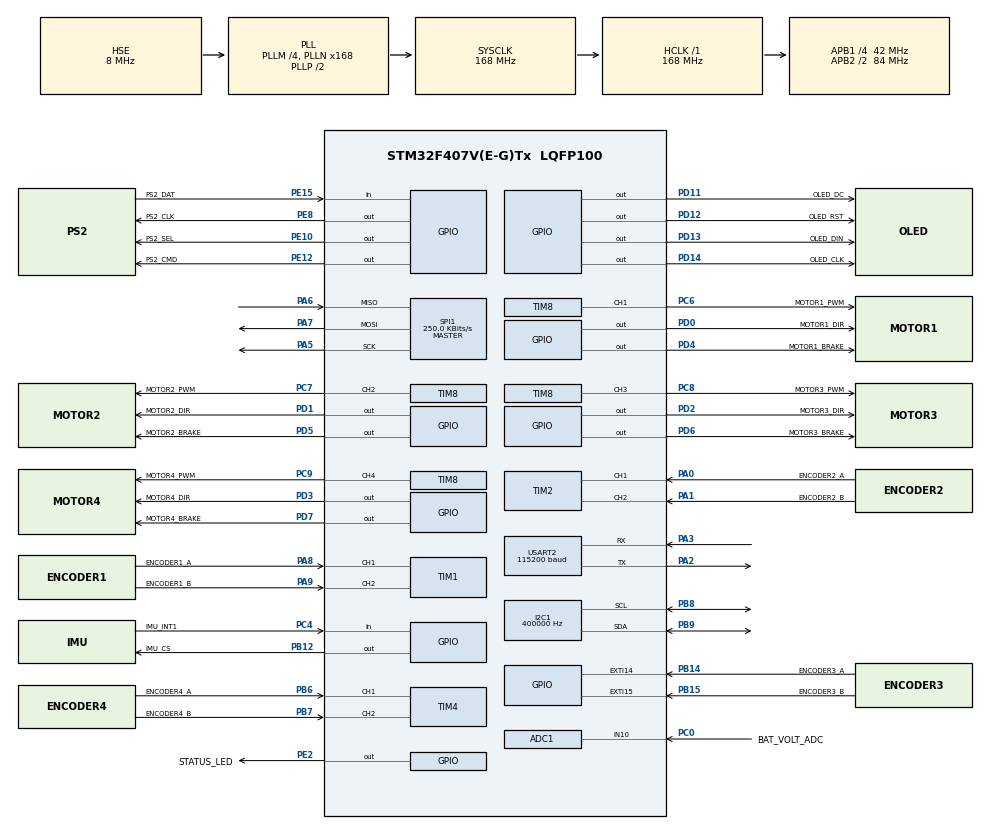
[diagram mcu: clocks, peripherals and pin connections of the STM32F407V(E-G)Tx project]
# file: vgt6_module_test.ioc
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ADC1.Channel-10\#ChannelRegularConversion=ADC_CHANNEL_10
ADC1.NbrOfConversionFlag=1
ADC1.Rank-10\#ChannelRegularConversion=1
ADC1.SamplingTime-10\#ChannelRegularConversion=ADC_SAMPLETIME_144CYCLES
ADC1.master=1
Dma.Request0=USART2_RX
Dma.Request1=USART2_TX
Dma.USART2_RX.0.Direction=DMA_PERIPH_TO_MEMORY
Dma.USART2_RX.0.FIFOMode=DMA_FIFOMODE_DISABLE
Dma.USART2_RX.0.Instance=DMA1_Stream5
Dma.USART2_RX.0.MemDataAlignment=DMA_MDATAALIGN_BYTE
Dma.USART2_RX.0.MemInc=DMA_MINC_ENABLE
Dma.USART2_RX.0.Mode=DMA_NORMAL
Dma.USART2_RX.0.PeriphDataAlignment=DMA_PDATAALIGN_BYTE
Dma.USART2_RX.0.PeriphInc=DMA_PINC_DISABLE
Dma.USART2_RX.0.Priority=DMA_PRIORITY_LOW
Dma.USART2_TX.1.Direction=DMA_MEMORY_TO_PERIPH
Dma.USART2_TX.1.FIFOMode=DMA_FIFOMODE_DISABLE
Dma.USART2_TX.1.Instance=DMA1_Stream6
Dma.USART2_TX.1.MemDataAlignment=DMA_MDATAALIGN_BYTE
Dma.USART2_TX.1.MemInc=DMA_MINC_ENABLE
Dma.USART2_TX.1.Mode=DMA_NORMAL
Dma.USART2_TX.1.PeriphDataAlignment=DMA_PDATAALIGN_BYTE
Dma.USART2_TX.1.PeriphInc=DMA_PINC_DISABLE
Dma.USART2_TX.1.Priority=DMA_PRIORITY_LOW
I2C1.ClockSpeed=400000
I2C1.I2C_Mode=I2C_Fast
Mcu.Family=STM32F4
Mcu.Name=STM32F407V(E-G)Tx
Mcu.Package=LQFP100
NVIC.DMA1_Stream5_IRQn=true\:5\:0\:false\:false\:true\:true\:true\:true
NVIC.DMA1_Stream6_IRQn=true\:5\:0\:false\:false\:true\:true\:true\:true
NVIC.EXTI15_10_IRQn=true\:5\:0\:false\:false\:true\:true\:true\:true
NVIC.I2C1_EV_IRQn=true\:5\:0\:false\:false\:true\:true\:true\:true
NVIC.I2C1_ER_IRQn=true\:5\:0\:false\:false\:true\:true\:true\:true
NVIC.PriorityGroup=NVIC_PRIORITYGROUP_4
NVIC.USART2_IRQn=true\:5\:0\:false\:false\:true\:true\:true\:true
PA0-WKUP.GPIO_Label=ENCODER2_A
PA0-WKUP.Signal=S_TIM2_CH1_ETR
PA1.GPIO_Label=ENCODER2_B
PA1.Signal=S_TIM2_CH2
PA13.Mode=Serial_Wire
PA13.Signal=SYS_JTMS-SWDIO
PA14.Mode=Serial_Wire
PA14.Signal=SYS_JTCK-SWCLK
PA2.Mode=Asynchronous
PA2.Signal=USART2_TX
PA3.Mode=Asynchronous
PA3.Signal=USART2_RX
PA5.Mode=Full_Duplex_Master
PA5.Signal=SPI1_SCK
PA6.Mode=Full_Duplex_Master
PA6.Signal=SPI1_MISO
PA7.Mode=Full_Duplex_Master
PA7.Signal=SPI1_MOSI
PA8.GPIO_Label=ENCODER1_A
PA8.Signal=S_TIM1_CH1
PA9.GPIO_Label=ENCODER1_B
PA9.Signal=S_TIM1_CH2
PB8.Mode=I2C
PB8.Signal=I2C1_SCL
PB9.Mode=I2C
PB9.Signal=I2C1_SDA
PB12.GPIO_Label=IMU_CS
PB12.GPIO_PuPd=GPIO_PULLUP
PB12.PinState=GPIO_PIN_SET
PB12.Signal=GPIO_Output
PB14.GPIO_Label=ENCODER3_A
PB14.GPIO_ModeDefaultEXTI=GPIO_MODE_IT_RISING_FALLING
PB14.Signal=GPXTI14
PB15.GPIO_Label=ENCODER3_B
PB15.GPIO_ModeDefaultEXTI=GPIO_MODE_IT_RISING_FALLING
PB15.Signal=GPXTI15
PB6.GPIO_Label=ENCODER4_A
PB6.Signal=S_TIM4_CH1
PB7.GPIO_Label=ENCODER4_B
PB7.Signal=S_TIM4_CH2
PE8.GPIO_Label=PS2_CLK
PE8.GPIO_PuPd=GPIO_PULLUP
PE8.PinState=GPIO_PIN_SET
PE8.Signal=GPIO_Output
PE10.GPIO_Label=PS2_SEL
PE10.GPIO_PuPd=GPIO_PULLUP
PE10.PinState=GPIO_PIN_SET
PE10.Signal=GPIO_Output
PE12.GPIO_Label=PS2_CMD
PE12.GPIO_PuPd=GPIO_PULLUP
PE12.PinState=GPIO_PIN_SET
PE12.Signal=GPIO_Output
PE15.GPIO_Label=PS2_DAT
PE15.GPIO_PuPd=GPIO_PULLUP
PE15.Signal=GPIO_Input
PC0.GPIO_Label=BAT_VOLT_ADC
PC0.Signal=ADCx_IN10
PC4.GPIO_Label=IMU_INT1
PC4.GPIO_PuPd=GPIO_PULLDOWN
PC4.Signal=GPIO_Input
PC6.GPIO_Label=MOTOR1_PWM
PC6.Signal=S_TIM8_CH1
PC7.GPIO_Label=MOTOR2_PWM
PC7.Signal=S_TIM8_CH2
PC8.GPIO_Label=MOTOR3_PWM
PC8.Signal=S_TIM8_CH3
PC9.GPIO_Label=MOTOR4_PWM
PC9.Signal=S_TIM8_CH4
PD0.GPIO_Label=MOTOR1_DIR
PD0.PinState=GPIO_PIN_RESET
PD0.Signal=GPIO_Output
PD1.GPIO_Label=MOTOR2_DIR
PD1.PinState=GPIO_PIN_RESET
PD1.Signal=GPIO_Output
PD11.GPIO_Label=OLED_DC
PD11.PinState=GPIO_PIN_RESET
PD11.Signal=GPIO_Output
PD12.GPIO_Label=OLED_RST
PD12.PinState=GPIO_PIN_SET
PD12.Signal=GPIO_Output
PD13.GPIO_Label=OLED_DIN
PD13.PinState=GPIO_PIN_SET
PD13.Signal=GPIO_Output
PD14.GPIO_Label=OLED_CLK
PD14.PinState=GPIO_PIN_SET
PD14.Signal=GPIO_Output
PD2.GPIO_Label=MOTOR3_DIR
PD2.PinState=GPIO_PIN_RESET
PD2.Signal=GPIO_Output
PD3.GPIO_Label=MOTOR4_DIR
PD3.PinState=GPIO_PIN_RESET
PD3.Signal=GPIO_Output
PD4.GPIO_Label=MOTOR1_BRAKE
PD4.PinState=GPIO_PIN_RESET
PD4.Signal=GPIO_Output
PD5.GPIO_Label=MOTOR2_BRAKE
PD5.PinState=GPIO_PIN_RESET
PD5.Signal=GPIO_Output
PD6.GPIO_Label=MOTOR3_BRAKE
PD6.PinState=GPIO_PIN_RESET
PD6.Signal=GPIO_Output
PD7.GPIO_Label=MOTOR4_BRAKE
PD7.PinState=GPIO_PIN_RESET
PD7.Signal=GPIO_Output
PE2.GPIO_Label=STATUS_LED
PE2.PinState=GPIO_PIN_RESET
PE2.Signal=GPIO_Output
PH0-OSC_IN.Mode=HSE-External-Oscillator
PH0-OSC_IN.Signal=RCC_OSC_IN
PH1-OSC_OUT.Mode=HSE-External-Oscillator
PH1-OSC_OUT.Signal=RCC_OSC_OUT
ProjectManager.HeapSize=0x200
ProjectManager.StackSize=0x1000
ProjectManager.TargetToolchain=MDK-ARM V5
RCC.48MHZClocksFreq_Value=84000000
RCC.AHBFreq_Value=168000000
RCC.APB1CLKDivider=RCC_HCLK_DIV4
RCC.APB1Freq_Value=42000000
RCC.APB1TimFreq_Value=84000000
RCC.APB2CLKDivider=RCC_HCLK_DIV2
RCC.APB2Freq_Value=84000000
RCC.APB2TimFreq_Value=168000000
RCC.CortexFreq_Value=168000000
RCC.HCLKFreq_Value=168000000
RCC.HSE_VALUE=8000000
RCC.HSI_VALUE=16000000
RCC.LSE_VALUE=32768
RCC.PLLM=4
RCC.PLLN=168
RCC.PLLSourceVirtual=RCC_PLLSOURCE_HSE
RCC.SYSCLKFreq_VALUE=168000000
RCC.SYSCLKSource=RCC_SYSCLKSOURCE_PLLCLK
RCC.VCOOutputFreq_Value=336000000
SH.ADCx_IN10.0=ADC1_IN10,IN10
SH.S_TIM1_CH1.0=TIM1_CH1,Encoder_Interface
SH.S_TIM1_CH2.0=TIM1_CH2,Encoder_Interface
SH.S_TIM2_CH1_ETR.0=TIM2_CH1,Encoder_Interface
SH.S_TIM2_CH2.0=TIM2_CH2,Encoder_Interface
SH.S_TIM4_CH1.0=TIM4_CH1,Encoder_Interface
SH.S_TIM4_CH2.0=TIM4_CH2,Encoder_Interface
SH.S_TIM8_CH1.0=TIM8_CH1,PWM Generation1 CH1
SH.S_TIM8_CH2.0=TIM8_CH2,PWM Generation2 CH2
SH.S_TIM8_CH3.0=TIM8_CH3,PWM Generation3 CH3
SH.S_TIM8_CH4.0=TIM8_CH4,PWM Generation4 CH4
SPI1.BaudRatePrescaler=SPI_BAUDRATEPRESCALER_64
SPI1.CLKPhase=SPI_PHASE_2EDGE
SPI1.CLKPolarity=SPI_POLARITY_HIGH
SPI1.CRCCalculation=SPI_CRCCALCULATION_DISABLE
SPI1.CalculateBaudRate=250.0 KBits/s
SPI1.DataSize=SPI_DATASIZE_8BIT
SPI1.Direction=SPI_DIRECTION_2LINES
SPI1.FirstBit=SPI_FIRSTBIT_MSB
SPI1.Mode=SPI_MODE_MASTER
SPI1.NSS=SPI_NSS_SOFT
SPI1.VirtualType=VM_MASTER
TIM1.EncoderMode=TIM_ENCODERMODE_TI12
TIM1.IC1Filter=10
TIM1.IC2Filter=10
TIM2.EncoderMode=TIM_ENCODERMODE_TI12
TIM2.IC1Filter=10
TIM2.IC2Filter=10
TIM4.EncoderMode=TIM_ENCODERMODE_TI12
TIM4.IC1Filter=10
TIM4.IC2Filter=10
TIM8.Channel-PWM\ Generation1\ CH1=TIM_CHANNEL_1
TIM8.Channel-PWM\ Generation2\ CH2=TIM_CHANNEL_2
TIM8.Channel-PWM\ Generation3\ CH3=TIM_CHANNEL_3
TIM8.Channel-PWM\ Generation4\ CH4=TIM_CHANNEL_4
TIM8.OCMode_PWM=TIM_OCMODE_PWM2
TIM8.Period=16799
TIM8.Prescaler=0
USART2.BaudRate=115200
USART2.VirtualMode=VM_ASYNC
board=custom

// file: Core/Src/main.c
/* USER CODE BEGIN Header */
/**
  ******************************************************************************
  * @file           : main.c
  * @brief          : Main program body
  ******************************************************************************
  * @attention
  *
  * Copyright (c) 2026 STMicroelectronics.
  * All rights reserved.
  *
  * This software is licensed under terms that can be found in the LICENSE file
  * in the root directory of this software component.
  * If no LICENSE file comes with this software, it is provided AS-IS.
  *
  ******************************************************************************
  */
/* USER CODE END Header */
#include "main.h"

/* USER CODE BEGIN Includes */
#include "app.h"
/* USER CODE END Includes */

ADC_HandleTypeDef hadc1;

I2C_HandleTypeDef hi2c1;

SPI_HandleTypeDef hspi1;

TIM_HandleTypeDef htim1;
TIM_HandleTypeDef htim2;
TIM_HandleTypeDef htim4;
TIM_HandleTypeDef htim8;

UART_HandleTypeDef huart2;
DMA_HandleTypeDef hdma_usart2_rx;
DMA_HandleTypeDef hdma_usart2_tx;

void SystemClock_Config(void);
static void MX_GPIO_Init(void);
static void MX_DMA_Init(void);
static void MX_ADC1_Init(void);
static void MX_I2C1_Init(void);
static void MX_SPI1_Init(void);
static void MX_TIM1_Init(void);
static void MX_TIM2_Init(void);
static void MX_TIM4_Init(void);
static void MX_TIM8_Init(void);
static void MX_USART2_UART_Init(void);

int main(void)
{

  /* MCU Configuration--------------------------------------------------------*/

  /* Reset of all peripherals, Initializes the Flash interface and the Systick. */
  HAL_Init();

  /* Configure the system clock */
  SystemClock_Config();

  /* Initialize all configured peripherals */
  MX_GPIO_Init();
  MX_DMA_Init();
  MX_ADC1_Init();
  MX_SPI1_Init();
  MX_TIM1_Init();
  MX_TIM2_Init();
  MX_TIM4_Init();
  MX_TIM8_Init();
  MX_USART2_UART_Init();
  MX_I2C1_Init();
  /* USER CODE BEGIN 2 */
  App_Init();
  /* USER CODE END 2 */

  /* Infinite loop */
  while (1)
  {

    /* USER CODE BEGIN 3 */
    App_Process();
  }
  /* USER CODE END 3 */
}

void SystemClock_Config(void)
{
  RCC_OscInitTypeDef RCC_OscInitStruct = {0};
  RCC_ClkInitTypeDef RCC_ClkInitStruct = {0};

  /** Configure the main internal regulator output voltage
  */
  __HAL_RCC_PWR_CLK_ENABLE();
  __HAL_PWR_VOLTAGESCALING_CONFIG(PWR_REGULATOR_VOLTAGE_SCALE1);

  /** Initializes the RCC Oscillators according to the specified parameters
  * in the RCC_OscInitTypeDef structure.
  */
  RCC_OscInitStruct.OscillatorType = RCC_OSCILLATORTYPE_HSE;
  RCC_OscInitStruct.HSEState = RCC_HSE_ON;
  RCC_OscInitStruct.PLL.PLLState = RCC_PLL_ON;
  RCC_OscInitStruct.PLL.PLLSource = RCC_PLLSOURCE_HSE;
  RCC_OscInitStruct.PLL.PLLM = 4;
  RCC_OscInitStruct.PLL.PLLN = 168;
  RCC_OscInitStruct.PLL.PLLP = RCC_PLLP_DIV2;
  RCC_OscInitStruct.PLL.PLLQ = 4;
  if (HAL_RCC_OscConfig(&RCC_OscInitStruct) != HAL_OK)
  {
    Error_Handler();
  }

  /** Initializes the CPU, AHB and APB buses clocks
  */
  RCC_ClkInitStruct.ClockType = RCC_CLOCKTYPE_HCLK|RCC_CLOCKTYPE_SYSCLK
                              |RCC_CLOCKTYPE_PCLK1|RCC_CLOCKTYPE_PCLK2;
  RCC_ClkInitStruct.SYSCLKSource = RCC_SYSCLKSOURCE_PLLCLK;
  RCC_ClkInitStruct.AHBCLKDivider = RCC_SYSCLK_DIV1;
  RCC_ClkInitStruct.APB1CLKDivider = RCC_HCLK_DIV4;
  RCC_ClkInitStruct.APB2CLKDivider = RCC_HCLK_DIV2;

  if (HAL_RCC_ClockConfig(&RCC_ClkInitStruct, FLASH_LATENCY_5) != HAL_OK)
  {
    Error_Handler();
  }
}

static void MX_ADC1_Init(void)
{

  ADC_ChannelConfTypeDef sConfig = {0};

  /** Configure the global features of the ADC (Clock, Resolution, Data Alignment and number of conversion)
  */
  hadc1.Instance = ADC1;
  hadc1.Init.ClockPrescaler = ADC_CLOCK_SYNC_PCLK_DIV4;
  hadc1.Init.Resolution = ADC_RESOLUTION_12B;
  hadc1.Init.ScanConvMode = DISABLE;
  hadc1.Init.ContinuousConvMode = DISABLE;
  hadc1.Init.DiscontinuousConvMode = DISABLE;
  hadc1.Init.ExternalTrigConvEdge = ADC_EXTERNALTRIGCONVEDGE_NONE;
  hadc1.Init.ExternalTrigConv = ADC_SOFTWARE_START;
  hadc1.Init.DataAlign = ADC_DATAALIGN_RIGHT;
  hadc1.Init.NbrOfConversion = 1;
  hadc1.Init.DMAContinuousRequests = DISABLE;
  hadc1.Init.EOCSelection = ADC_EOC_SINGLE_CONV;
  if (HAL_ADC_Init(&hadc1) != HAL_OK)
  {
    Error_Handler();
  }

  /** Configure for the selected ADC regular channel its corresponding rank in the sequencer and its sample time.
  */
  sConfig.Channel = ADC_CHANNEL_10;
  sConfig.Rank = 1;
  sConfig.SamplingTime = ADC_SAMPLETIME_144CYCLES;
  if (HAL_ADC_ConfigChannel(&hadc1, &sConfig) != HAL_OK)
  {
    Error_Handler();
  }

}

static void MX_SPI1_Init(void)
{

  /* SPI1 parameter configuration*/
  hspi1.Instance = SPI1;
  hspi1.Init.Mode = SPI_MODE_MASTER;
  hspi1.Init.Direction = SPI_DIRECTION_2LINES;
  hspi1.Init.DataSize = SPI_DATASIZE_8BIT;
  hspi1.Init.CLKPolarity = SPI_POLARITY_HIGH;
  hspi1.Init.CLKPhase = SPI_PHASE_2EDGE;
  hspi1.Init.NSS = SPI_NSS_SOFT;
  hspi1.Init.BaudRatePrescaler = SPI_BAUDRATEPRESCALER_64;
  hspi1.Init.FirstBit = SPI_FIRSTBIT_MSB;
  hspi1.Init.TIMode = SPI_TIMODE_DISABLE;
  hspi1.Init.CRCCalculation = SPI_CRCCALCULATION_DISABLE;
  hspi1.Init.CRCPolynomial = 10;
  if (HAL_SPI_Init(&hspi1) != HAL_OK)
  {
    Error_Handler();
  }

}

static void MX_TIM1_Init(void)
{

  TIM_Encoder_InitTypeDef sConfig = {0};
  TIM_MasterConfigTypeDef sMasterConfig = {0};

  htim1.Instance = TIM1;
  htim1.Init.Prescaler = 0;
  htim1.Init.CounterMode = TIM_COUNTERMODE_UP;
  htim1.Init.Period = 65535;
  htim1.Init.ClockDivision = TIM_CLOCKDIVISION_DIV1;
  htim1.Init.RepetitionCounter = 0;
  htim1.Init.AutoReloadPreload = TIM_AUTORELOAD_PRELOAD_DISABLE;
  sConfig.EncoderMode = TIM_ENCODERMODE_TI12;
  sConfig.IC1Polarity = TIM_ICPOLARITY_RISING;
  sConfig.IC1Selection = TIM_ICSELECTION_DIRECTTI;
  sConfig.IC1Prescaler = TIM_ICPSC_DIV1;
  sConfig.IC1Filter = 10;
  sConfig.IC2Polarity = TIM_ICPOLARITY_RISING;
  sConfig.IC2Selection = TIM_ICSELECTION_DIRECTTI;
  sConfig.IC2Prescaler = TIM_ICPSC_DIV1;
  sConfig.IC2Filter = 10;
  if (HAL_TIM_Encoder_Init(&htim1, &sConfig) != HAL_OK)
  {
    Error_Handler();
  }
  sMasterConfig.MasterOutputTrigger = TIM_TRGO_RESET;
  sMasterConfig.MasterSlaveMode = TIM_MASTERSLAVEMODE_DISABLE;
  if (HAL_TIMEx_MasterConfigSynchronization(&htim1, &sMasterConfig) != HAL_OK)
  {
    Error_Handler();
  }

}

static void MX_TIM2_Init(void)
{

  TIM_Encoder_InitTypeDef sConfig = {0};
  TIM_MasterConfigTypeDef sMasterConfig = {0};

  htim2.Instance = TIM2;
  htim2.Init.Prescaler = 0;
  htim2.Init.CounterMode = TIM_COUNTERMODE_UP;
  htim2.Init.Period = 4294967295;
  htim2.Init.ClockDivision = TIM_CLOCKDIVISION_DIV1;
  htim2.Init.AutoReloadPreload = TIM_AUTORELOAD_PRELOAD_DISABLE;
  sConfig.EncoderMode = TIM_ENCODERMODE_TI12;
  sConfig.IC1Polarity = TIM_ICPOLARITY_RISING;
  sConfig.IC1Selection = TIM_ICSELECTION_DIRECTTI;
  sConfig.IC1Prescaler = TIM_ICPSC_DIV1;
  sConfig.IC1Filter = 10;
  sConfig.IC2Polarity = TIM_ICPOLARITY_RISING;
  sConfig.IC2Selection = TIM_ICSELECTION_DIRECTTI;
  sConfig.IC2Prescaler = TIM_ICPSC_DIV1;
  sConfig.IC2Filter = 10;
  if (HAL_TIM_Encoder_Init(&htim2, &sConfig) != HAL_OK)
  {
    Error_Handler();
  }
  sMasterConfig.MasterOutputTrigger = TIM_TRGO_RESET;
  sMasterConfig.MasterSlaveMode = TIM_MASTERSLAVEMODE_DISABLE;
  if (HAL_TIMEx_MasterConfigSynchronization(&htim2, &sMasterConfig) != HAL_OK)
  {
    Error_Handler();
  }

}

static void MX_TIM4_Init(void)
{

  TIM_Encoder_InitTypeDef sConfig = {0};
  TIM_MasterConfigTypeDef sMasterConfig = {0};

  htim4.Instance = TIM4;
  htim4.Init.Prescaler = 0;
  htim4.Init.CounterMode = TIM_COUNTERMODE_UP;
  htim4.Init.Period = 65535;
  htim4.Init.ClockDivision = TIM_CLOCKDIVISION_DIV1;
  htim4.Init.AutoReloadPreload = TIM_AUTORELOAD_PRELOAD_DISABLE;
  sConfig.EncoderMode = TIM_ENCODERMODE_TI12;
  sConfig.IC1Polarity = TIM_ICPOLARITY_RISING;
  sConfig.IC1Selection = TIM_ICSELECTION_DIRECTTI;
  sConfig.IC1Prescaler = TIM_ICPSC_DIV1;
  sConfig.IC1Filter = 10;
  sConfig.IC2Polarity = TIM_ICPOLARITY_RISING;
  sConfig.IC2Selection = TIM_ICSELECTION_DIRECTTI;
  sConfig.IC2Prescaler = TIM_ICPSC_DIV1;
  sConfig.IC2Filter = 10;
  if (HAL_TIM_Encoder_Init(&htim4, &sConfig) != HAL_OK)
  {
    Error_Handler();
  }
  sMasterConfig.MasterOutputTrigger = TIM_TRGO_RESET;
  sMasterConfig.MasterSlaveMode = TIM_MASTERSLAVEMODE_DISABLE;
  if (HAL_TIMEx_MasterConfigSynchronization(&htim4, &sMasterConfig) != HAL_OK)
  {
    Error_Handler();
  }

}

static void MX_TIM8_Init(void)
{

  TIM_MasterConfigTypeDef sMasterConfig = {0};
  TIM_OC_InitTypeDef sConfigOC = {0};
  TIM_BreakDeadTimeConfigTypeDef sBreakDeadTimeConfig = {0};

  htim8.Instance = TIM8;
  htim8.Init.Prescaler = 0;
  htim8.Init.CounterMode = TIM_COUNTERMODE_UP;
  htim8.Init.Period = 16799;
  htim8.Init.ClockDivision = TIM_CLOCKDIVISION_DIV1;
  htim8.Init.RepetitionCounter = 0;
  htim8.Init.AutoReloadPreload = TIM_AUTORELOAD_PRELOAD_DISABLE;
  if (HAL_TIM_PWM_Init(&htim8) != HAL_OK)
  {
    Error_Handler();
  }
  sMasterConfig.MasterOutputTrigger = TIM_TRGO_RESET;
  sMasterConfig.MasterSlaveMode = TIM_MASTERSLAVEMODE_DISABLE;
  if (HAL_TIMEx_MasterConfigSynchronization(&htim8, &sMasterConfig) != HAL_OK)
  {
    Error_Handler();
  }
  sConfigOC.OCMode = TIM_OCMODE_PWM2;
  sConfigOC.Pulse = 0;
  sConfigOC.OCPolarity = TIM_OCPOLARITY_HIGH;
  sConfigOC.OCNPolarity = TIM_OCNPOLARITY_HIGH;
  sConfigOC.OCFastMode = TIM_OCFAST_DISABLE;
  sConfigOC.OCIdleState = TIM_OCIDLESTATE_RESET;
  sConfigOC.OCNIdleState = TIM_OCNIDLESTATE_RESET;
  if (HAL_TIM_PWM_ConfigChannel(&htim8, &sConfigOC, TIM_CHANNEL_1) != HAL_OK)
  {
    Error_Handler();
  }
  if (HAL_TIM_PWM_ConfigChannel(&htim8, &sConfigOC, TIM_CHANNEL_2) != HAL_OK)
  {
    Error_Handler();
  }
  if (HAL_TIM_PWM_ConfigChannel(&htim8, &sConfigOC, TIM_CHANNEL_3) != HAL_OK)
  {
    Error_Handler();
  }
  if (HAL_TIM_PWM_ConfigChannel(&htim8, &sConfigOC, TIM_CHANNEL_4) != HAL_OK)
  {
    Error_Handler();
  }
  sBreakDeadTimeConfig.OffStateRunMode = TIM_OSSR_DISABLE;
  sBreakDeadTimeConfig.OffStateIDLEMode = TIM_OSSI_DISABLE;
  sBreakDeadTimeConfig.LockLevel = TIM_LOCKLEVEL_OFF;
  sBreakDeadTimeConfig.DeadTime = 0;
  sBreakDeadTimeConfig.BreakState = TIM_BREAK_DISABLE;
  sBreakDeadTimeConfig.BreakPolarity = TIM_BREAKPOLARITY_HIGH;
  sBreakDeadTimeConfig.AutomaticOutput = TIM_AUTOMATICOUTPUT_DISABLE;
  if (HAL_TIMEx_ConfigBreakDeadTime(&htim8, &sBreakDeadTimeConfig) != HAL_OK)
  {
    Error_Handler();
  }
  HAL_TIM_MspPostInit(&htim8);

}

static void MX_USART2_UART_Init(void)
{

  huart2.Instance = USART2;
  huart2.Init.BaudRate = 115200;
  huart2.Init.WordLength = UART_WORDLENGTH_8B;
  huart2.Init.StopBits = UART_STOPBITS_1;
  huart2.Init.Parity = UART_PARITY_NONE;
  huart2.Init.Mode = UART_MODE_TX_RX;
  huart2.Init.HwFlowCtl = UART_HWCONTROL_NONE;
  huart2.Init.OverSampling = UART_OVERSAMPLING_16;
  if (HAL_UART_Init(&huart2) != HAL_OK)
  {
    Error_Handler();
  }

}

static void MX_DMA_Init(void)
{

  /* DMA controller clock enable */
  __HAL_RCC_DMA1_CLK_ENABLE();

  /* DMA interrupt init */
  /* DMA1_Stream5_IRQn interrupt configuration */
  HAL_NVIC_SetPriority(DMA1_Stream5_IRQn, 5, 0);
  HAL_NVIC_EnableIRQ(DMA1_Stream5_IRQn);
  /* DMA1_Stream6_IRQn interrupt configuration */
  HAL_NVIC_SetPriority(DMA1_Stream6_IRQn, 5, 0);
  HAL_NVIC_EnableIRQ(DMA1_Stream6_IRQn);

}

static void MX_GPIO_Init(void)
{
  GPIO_InitTypeDef GPIO_InitStruct = {0};

  /* GPIO Ports Clock Enable */
  __HAL_RCC_GPIOE_CLK_ENABLE();
  __HAL_RCC_GPIOH_CLK_ENABLE();
  __HAL_RCC_GPIOC_CLK_ENABLE();
  __HAL_RCC_GPIOA_CLK_ENABLE();
  __HAL_RCC_GPIOB_CLK_ENABLE();
  __HAL_RCC_GPIOD_CLK_ENABLE();

  /*Configure GPIO pin Output Level */
  HAL_GPIO_WritePin(STATUS_LED_GPIO_Port, STATUS_LED_Pin, GPIO_PIN_RESET);

  /*Configure GPIO pin Output Level */
  HAL_GPIO_WritePin(IMU_CS_GPIO_Port, IMU_CS_Pin, GPIO_PIN_SET);

  /*Configure GPIO pin Output Level */
  HAL_GPIO_WritePin(GPIOD, OLED_DC_Pin|MOTOR1_DIR_Pin|MOTOR2_DIR_Pin|MOTOR3_DIR_Pin
                          |MOTOR4_DIR_Pin|MOTOR1_BRAKE_Pin|MOTOR2_BRAKE_Pin|MOTOR3_BRAKE_Pin
                          |MOTOR4_BRAKE_Pin, GPIO_PIN_RESET);

  /*Configure GPIO pin Output Level */
  HAL_GPIO_WritePin(GPIOD, OLED_RST_Pin|OLED_DIN_Pin|OLED_CLK_Pin, GPIO_PIN_SET);

  /*Configure GPIO pin : STATUS_LED_Pin */
  GPIO_InitStruct.Pin = STATUS_LED_Pin;
  GPIO_InitStruct.Mode = GPIO_MODE_OUTPUT_PP;
  GPIO_InitStruct.Pull = GPIO_NOPULL;
  GPIO_InitStruct.Speed = GPIO_SPEED_FREQ_LOW;
  HAL_GPIO_Init(STATUS_LED_GPIO_Port, &GPIO_InitStruct);

  /*Configure GPIO pin : IMU_INT1_Pin */
  GPIO_InitStruct.Pin = IMU_INT1_Pin;
  GPIO_InitStruct.Mode = GPIO_MODE_INPUT;
  GPIO_InitStruct.Pull = GPIO_PULLDOWN;
  HAL_GPIO_Init(IMU_INT1_GPIO_Port, &GPIO_InitStruct);

  /*Configure GPIO pin : IMU_CS_Pin */
  GPIO_InitStruct.Pin = IMU_CS_Pin;
  GPIO_InitStruct.Mode = GPIO_MODE_OUTPUT_PP;
  GPIO_InitStruct.Pull = GPIO_PULLUP;
  GPIO_InitStruct.Speed = GPIO_SPEED_FREQ_LOW;
  HAL_GPIO_Init(IMU_CS_GPIO_Port, &GPIO_InitStruct);

  /*Configure GPIO pins : ENCODER3_A_Pin ENCODER3_B_Pin */
  GPIO_InitStruct.Pin = ENCODER3_A_Pin|ENCODER3_B_Pin;
  GPIO_InitStruct.Mode = GPIO_MODE_IT_RISING_FALLING;
  GPIO_InitStruct.Pull = GPIO_NOPULL;
  HAL_GPIO_Init(GPIOB, &GPIO_InitStruct);

  /*Configure GPIO pins : OLED_DC_Pin OLED_RST_Pin OLED_DIN_Pin OLED_CLK_Pin
                           MOTOR1_DIR_Pin MOTOR2_DIR_Pin MOTOR3_DIR_Pin MOTOR4_DIR_Pin
                           MOTOR1_BRAKE_Pin MOTOR2_BRAKE_Pin MOTOR3_BRAKE_Pin MOTOR4_BRAKE_Pin */
  GPIO_InitStruct.Pin = OLED_DC_Pin|OLED_RST_Pin|OLED_DIN_Pin|OLED_CLK_Pin
                          |MOTOR1_DIR_Pin|MOTOR2_DIR_Pin|MOTOR3_DIR_Pin|MOTOR4_DIR_Pin
                          |MOTOR1_BRAKE_Pin|MOTOR2_BRAKE_Pin|MOTOR3_BRAKE_Pin|MOTOR4_BRAKE_Pin;
  GPIO_InitStruct.Mode = GPIO_MODE_OUTPUT_PP;
  GPIO_InitStruct.Pull = GPIO_NOPULL;
  GPIO_InitStruct.Speed = GPIO_SPEED_FREQ_LOW;
  HAL_GPIO_Init(GPIOD, &GPIO_InitStruct);

  /* EXTI interrupt init*/
  HAL_NVIC_SetPriority(EXTI15_10_IRQn, 5, 0);
  HAL_NVIC_EnableIRQ(EXTI15_10_IRQn);

}

static void MX_I2C1_Init(void)
{

  hi2c1.Instance = I2C1;
  hi2c1.Init.ClockSpeed = 400000;
  hi2c1.Init.DutyCycle = I2C_DUTYCYCLE_2;
  hi2c1.Init.OwnAddress1 = 0;
  hi2c1.Init.AddressingMode = I2C_ADDRESSINGMODE_7BIT;
  hi2c1.Init.DualAddressMode = I2C_DUALADDRESS_DISABLE;
  hi2c1.Init.OwnAddress2 = 0;
  hi2c1.Init.GeneralCallMode = I2C_GENERALCALL_DISABLE;
  hi2c1.Init.NoStretchMode = I2C_NOSTRETCH_DISABLE;
  if (HAL_I2C_Init(&hi2c1) != HAL_OK)
  {
    Error_Handler();
  }

}

void Error_Handler(void)
{
  __disable_irq();
  while (1)
  {
  }
}
